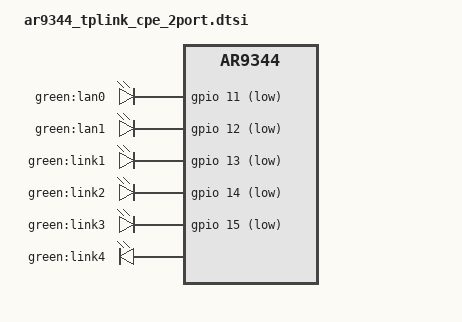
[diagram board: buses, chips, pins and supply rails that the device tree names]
// SPDX-License-Identifier: GPL-2.0-or-later OR MIT

#include "ar9344_tplink_cpe.dtsi"

/ {
	aliases {
		led-boot = &led_link4;
		led-failsafe = &led_link4;
		led-running = &led_link4;
		led-upgrade = &led_link4;
	};

	leds {
		compatible = "gpio-leds";

		lan0 {
			label = "green:lan0";
			gpios = <&gpio 11 GPIO_ACTIVE_LOW>;
		};

		lan1 {
			label = "green:lan1";
			gpios = <&gpio 12 GPIO_ACTIVE_LOW>;
		};

		link1 {
			label = "green:link1";
			gpios = <&gpio 13 GPIO_ACTIVE_LOW>;
		};

		link2 {
			label = "green:link2";
			gpios = <&gpio 14 GPIO_ACTIVE_LOW>;
		};

		link3 {
			label = "green:link3";
			gpios = <&gpio 15 GPIO_ACTIVE_LOW>;
		};

		led_link4: link4 {
			label = "green:link4";
		};
	};
};

&eth1 {
	nvmem-cells = <&macaddr_info_8>;
	nvmem-cell-names = "mac-address";

	gmac-config {
		device = <&gmac>;
		switch-phy-swap = <0>;
		switch-only-mode = <1>;
	};
};
